VERSION "1.24"

NS_ :

BS_:

BU_: ECU_BODY ECU_CLUSTER

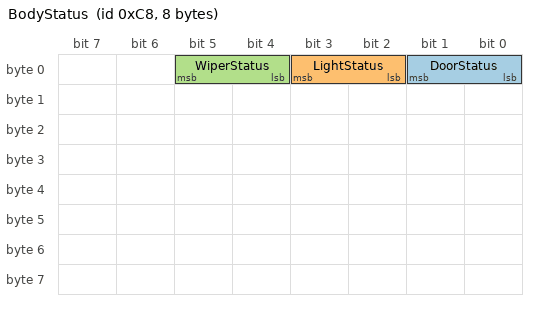
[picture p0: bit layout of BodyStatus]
BO_ 200 BodyStatus: 8 ECU_BODY
 SG_ DoorStatus : 0|2@1+ (1,0) [0|3] "" ECU_CLUSTER
 SG_ LightStatus : 2|2@1+ (1,0) [0|3] "" ECU_CLUSTER
 SG_ WiperStatus : 4|2@1+ (1,0) [0|3] "" ECU_CLUSTER

BO_ 201 ClusterInfo: 8 ECU_CLUSTER
 SG
